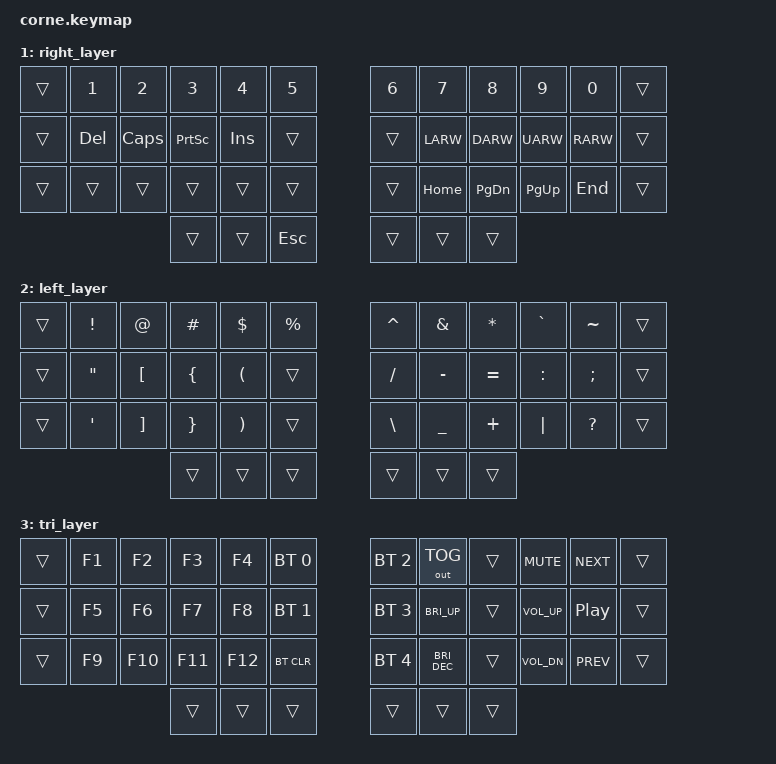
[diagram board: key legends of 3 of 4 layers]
// Copyright (c) 2022 The ZMK Contributors
// SPDX-License-Identifier: MIT

#include <behaviors.dtsi>
#include <dt-bindings/zmk/keys.h>
#include <dt-bindings/zmk/bt.h>
#include <dt-bindings/zmk/outputs.h>

// Home row mods macro
// force rebuild
#define WHRML(k2,k3,k4) &ht LALT k2  &ht LGUI k3  &ht LCTRL k4
#define WHRMR(k1,k2,k3) &ht RCTRL k1  &ht RGUI k2  &ht RALT k3

#define LAYBASE 0
#define LAYRIGHT 1
#define LAYLEFT 2
#define LAYBOTH 3

/ {
    behaviors {
        ht: hold_tap {
            label = "hold_tap";
            compatible = "zmk,behavior-hold-tap";
            #binding-cells = <2>;
            flavor = "tap-preferred";
            tapping-term-ms = <220>;
            quick-tap-ms = <150>;
            global-quick-tap;
            bindings = <&kp>, <&kp>;
        };
    };

    conditional_layers {
        compatible = "zmk,conditional-layers";
        tri_layer {
            if-layers = <LAYRIGHT LAYLEFT>;
            then-layer = <LAYBOTH>;
        };
    };

    keymap {
        compatible = "zmk,keymap";
        default_layer {
            bindings = <
            &trans   &kp Q   &kp W   &kp E   &kp R   &kp T        &kp Y   &kp U   &kp I   &kp O   &kp P              &trans
            &trans   &kp A  WHRML(S,      D,     F)  &kp G        &kp H  WHRMR(J,     K,      L)  &kp BSPC           &trans
            &trans   &kp Z   &kp X   &kp C   &kp V   &kp B        &kp N   &kp M   &kp COMMA  &kp DOT  &kp ENTER      &trans


              &kp LSHIFT    &lt LAYLEFT ESC &kp SPACE      &kp ENTER    &lt LAYRIGHT TAB  &kp LALT
            >;
        };



        right_layer {
            bindings = <
            &trans   &kp N1    &kp N2     &kp N3     &kp N4    &kp N5          &kp N6     &kp N7     &kp N8     &kp N9     &kp N0    &trans
            &trans   &kp DEL   &kp CAPS   &kp PSCRN  &kp INS   &trans          &trans     &kp LARW   &kp DARW   &kp UARW   &kp RARW  &trans
            &trans   &trans    &trans     &trans     &trans    &trans          &trans     &kp HOME   &kp PG_DN  &kp PG_UP  &kp END   &trans
                                    &trans           &trans     &kp ESC             &trans     &trans     &trans
            >;
        };

        left_layer {
            bindings = <
        //╭──────────┬──────────┬──────────┬──────────┬──────────╮   ╭──────────┬──────────┬──────────┬──────────┬──────────╮
        //│  !       │  @       │  #       │  $       │  %       │   │  ^       │  &       │  *       │  `       │  ~       │
 &trans  &kp EXCL   &kp AT     &kp HASH   &kp DLLR   &kp PRCNT      &kp CARET  &kp AMPS   &kp ASTRK  &kp GRAVE   &kp TILDE  &trans
        //├──────────┼──────────┼──────────┼──────────┼──────────┤   ├──────────┼──────────┼──────────┼──────────┼──────────┤
        //│  "       │  [       │  {       │  (       │          │   │   /      │  -       │  =       │     :    │  ;       │
 &trans  &kp DQT  &kp LBKT   &kp LBRC   &kp LPAR   &trans         &kp FSLH   &kp MINUS  &kp EQUAL  &kp COLON   &kp SEMI     &trans
        //├──────────┼──────────┼──────────┼──────────┼──────────┤   ├──────────┼──────────┼──────────┼──────────┼──────────┤
        //│  '       │  ]       │  }       │  )       │          │   │    \     │  _       │  +       │  │       │   ?      │
 &trans  &kp SQT     &kp RBKT   &kp RBRC   &kp RPAR   &trans         &kp BSLH   &kp UNDER  &kp PLUS   &kp PIPE  &kp QMARK   &trans
        //╰──────────┴──────────┴──────────┼──────────┼──────────┤   ├──────────┼──────────┼──────────┴──────────┴──────────╯
                                    &trans     &trans     &trans      &trans   &trans     &trans
        //                                 ╰──────────┴──────────╯   ╰──────────┴──────────╯
            >;
        };

        tri_layer {
            bindings = <
&trans   &kp F1     &kp F2     &kp F3     &kp F4     &bt BT_SEL 0     &bt BT_SEL 2  &out OUT_TOG  &trans  &kp C_MUTE  &kp C_NEXT    &trans
&trans   &kp F5     &kp F6     &kp F7     &kp F8     &bt BT_SEL 1     &bt BT_SEL 3  &kp C_BRI_UP  &trans   &kp C_VOL_UP  &kp C_PP    &trans
&trans   &kp F9     &kp F10    &kp F11    &kp F12     &bt BT_CLR      &bt BT_SEL 4  &kp C_BRI_DEC &trans  &kp C_VOL_DN &kp C_PREV  &trans
                                       &trans     &trans     &trans         &trans     &trans   &trans
            >;
        };
    };
};
